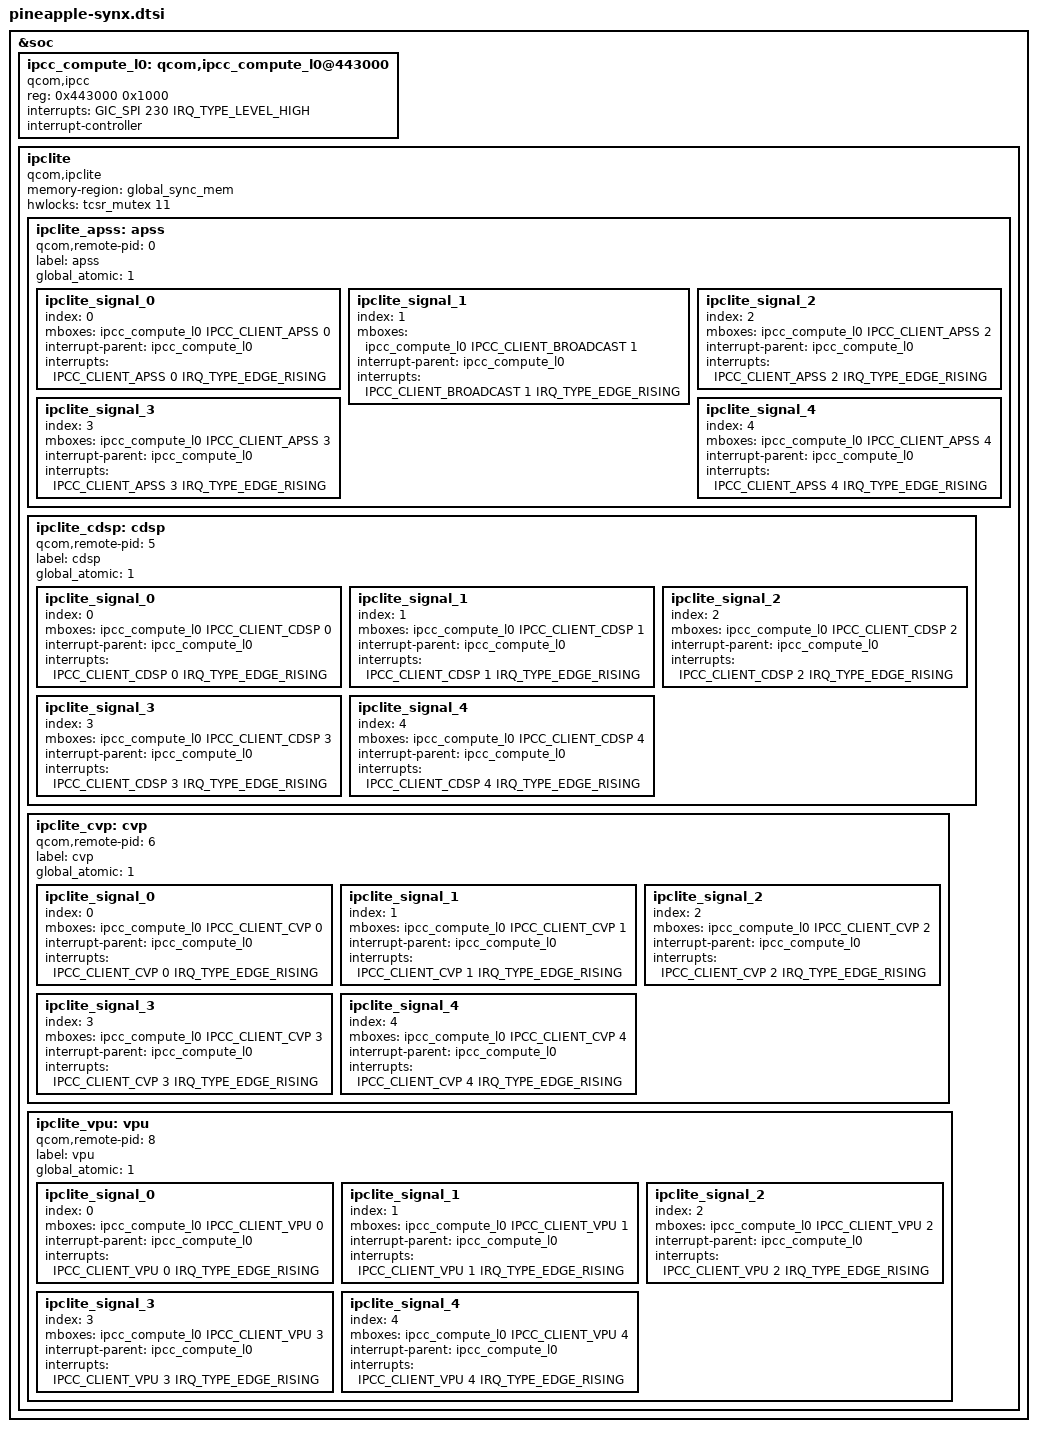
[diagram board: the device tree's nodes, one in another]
&soc {
	#address-cells = <1>;
	#size-cells = <1>;

	ipcc_compute_l0: qcom,ipcc_compute_l0@443000 {
		compatible = "qcom,ipcc";
		reg = <0x443000 0x1000>;
		interrupts = <GIC_SPI 230 IRQ_TYPE_LEVEL_HIGH>;
		interrupt-controller;
		#interrupt-cells = <3>;
		#mbox-cells = <2>;
	};
	ipclite {
		compatible = "qcom,ipclite";
		memory-region = <&global_sync_mem>;
		hwlocks = <&tcsr_mutex 11>;
		#address-cells = <1>;
		#size-cells = <1>;
		ranges;

		ipclite_apss: apss {
			qcom,remote-pid = <0>;
			label = "apss";
			global_atomic = <1>;

			ipclite_signal_0 {
				index = <0>;
				mboxes = <&ipcc_compute_l0 IPCC_CLIENT_APSS
					0>;
					interrupt-parent = <&ipcc_compute_l0>;
				interrupts = <IPCC_CLIENT_APSS
					0
					IRQ_TYPE_EDGE_RISING>;
			};

			ipclite_signal_1 {
				index = <1>;
				mboxes = <&ipcc_compute_l0 IPCC_CLIENT_BROADCAST
					1>;
				interrupt-parent = <&ipcc_compute_l0>;
				interrupts = <IPCC_CLIENT_BROADCAST
					1
					IRQ_TYPE_EDGE_RISING>;
			};

			ipclite_signal_2 {
				index = <2>;
				mboxes = <&ipcc_compute_l0 IPCC_CLIENT_APSS
					2>;
				interrupt-parent = <&ipcc_compute_l0>;
				interrupts = <IPCC_CLIENT_APSS
					2
					IRQ_TYPE_EDGE_RISING>;
			};

			ipclite_signal_3 {
				index = <3>;
				mboxes = <&ipcc_compute_l0 IPCC_CLIENT_APSS
					3>;
				interrupt-parent = <&ipcc_compute_l0>;
				interrupts = <IPCC_CLIENT_APSS
					3
					IRQ_TYPE_EDGE_RISING>;
			};

			ipclite_signal_4 {
				index = <4>;
				mboxes = <&ipcc_compute_l0 IPCC_CLIENT_APSS
					4>;
				interrupt-parent = <&ipcc_compute_l0>;
				interrupts = <IPCC_CLIENT_APSS
					4
					IRQ_TYPE_EDGE_RISING>;
			};
		};

		ipclite_cdsp: cdsp {
			qcom,remote-pid = <5>;
			label = "cdsp";
			global_atomic = <1>;

			ipclite_signal_0 {
				index = <0>;
				mboxes = <&ipcc_compute_l0 IPCC_CLIENT_CDSP
					0>;
				interrupt-parent = <&ipcc_compute_l0>;
				interrupts = <IPCC_CLIENT_CDSP
					0
					IRQ_TYPE_EDGE_RISING>;
			};

			ipclite_signal_1 {
				index = <1>;
				mboxes = <&ipcc_compute_l0 IPCC_CLIENT_CDSP
					1>;
				interrupt-parent = <&ipcc_compute_l0>;
				interrupts = <IPCC_CLIENT_CDSP
					1
					IRQ_TYPE_EDGE_RISING>;
			};

			ipclite_signal_2 {
				index = <2>;
				mboxes = <&ipcc_compute_l0 IPCC_CLIENT_CDSP
					2>;
				interrupt-parent = <&ipcc_compute_l0>;
				interrupts = <IPCC_CLIENT_CDSP
					2
					IRQ_TYPE_EDGE_RISING>;
			};

			ipclite_signal_3 {
				index = <3>;
				mboxes = <&ipcc_compute_l0 IPCC_CLIENT_CDSP
					3>;
				interrupt-parent = <&ipcc_compute_l0>;
				interrupts = <IPCC_CLIENT_CDSP
					3
					IRQ_TYPE_EDGE_RISING>;
			};

			ipclite_signal_4 {
				index = <4>;
				mboxes = <&ipcc_compute_l0 IPCC_CLIENT_CDSP
					4>;
				interrupt-parent = <&ipcc_compute_l0>;
				interrupts = <IPCC_CLIENT_CDSP
					4
					IRQ_TYPE_EDGE_RISING>;
			};
		};

		ipclite_cvp: cvp {
			qcom,remote-pid = <6>;
			label = "cvp";
			global_atomic = <1>;

			ipclite_signal_0 {
				index = <0>;
				mboxes = <&ipcc_compute_l0 IPCC_CLIENT_CVP
					0>;
				interrupt-parent = <&ipcc_compute_l0>;
				interrupts = <IPCC_CLIENT_CVP
					0
					IRQ_TYPE_EDGE_RISING>;
			};

			ipclite_signal_1 {
				index = <1>;
				mboxes = <&ipcc_compute_l0 IPCC_CLIENT_CVP
					1>;
				interrupt-parent = <&ipcc_compute_l0>;
				interrupts = <IPCC_CLIENT_CVP
					1
					IRQ_TYPE_EDGE_RISING>;
			};

			ipclite_signal_2 {
				index = <2>;
				mboxes = <&ipcc_compute_l0 IPCC_CLIENT_CVP
					2>;
				interrupt-parent = <&ipcc_compute_l0>;
				interrupts = <IPCC_CLIENT_CVP
					2
					IRQ_TYPE_EDGE_RISING>;
			};

			ipclite_signal_3 {
				index = <3>;
				mboxes = <&ipcc_compute_l0 IPCC_CLIENT_CVP
					3>;
				interrupt-parent = <&ipcc_compute_l0>;
				interrupts = <IPCC_CLIENT_CVP
					3
					IRQ_TYPE_EDGE_RISING>;
			};

			ipclite_signal_4 {
				index = <4>;
				mboxes = <&ipcc_compute_l0 IPCC_CLIENT_CVP
					4>;
				interrupt-parent = <&ipcc_compute_l0>;
				interrupts = <IPCC_CLIENT_CVP
					4
					IRQ_TYPE_EDGE_RISING>;
			};
		};

		ipclite_vpu: vpu {
			qcom,remote-pid = <8>;
			label = "vpu";
			global_atomic = <1>;

			ipclite_signal_0 {
				index = <0>;
				mboxes = <&ipcc_compute_l0 IPCC_CLIENT_VPU
					0>;
				interrupt-parent = <&ipcc_compute_l0>;
				interrupts = <IPCC_CLIENT_VPU
					0
					IRQ_TYPE_EDGE_RISING>;
			};

			ipclite_signal_1 {
				index = <1>;
				mboxes = <&ipcc_compute_l0 IPCC_CLIENT_VPU
					1>;
				interrupt-parent = <&ipcc_compute_l0>;
				interrupts = <IPCC_CLIENT_VPU
					1
					IRQ_TYPE_EDGE_RISING>;
			};

			ipclite_signal_2 {
				index = <2>;
				mboxes = <&ipcc_compute_l0 IPCC_CLIENT_VPU
					2>;
				interrupt-parent = <&ipcc_compute_l0>;
				interrupts = <IPCC_CLIENT_VPU
					2
					IRQ_TYPE_EDGE_RISING>;
			};

			ipclite_signal_3 {
				index = <3>;
				mboxes = <&ipcc_compute_l0 IPCC_CLIENT_VPU
					3>;
				interrupt-parent = <&ipcc_compute_l0>;
				interrupts = <IPCC_CLIENT_VPU
					3
					IRQ_TYPE_EDGE_RISING>;
			};

			ipclite_signal_4 {
				index = <4>;
				mboxes = <&ipcc_compute_l0 IPCC_CLIENT_VPU
					4>;
				interrupt-parent = <&ipcc_compute_l0>;
				interrupts = <IPCC_CLIENT_VPU
					4
					IRQ_TYPE_EDGE_RISING>;
			};
		};
	};

};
